# STM32G484 register map
File version: 2.8
CPU: CM4 r0p1, little endian, MPU, FPU, 4 interrupt priority bits
Registers are 32-bit, read-write, reset 0x0 unless marked. A register's access mark holds for its fields unless they carry their own. Offsets are from the block's base; [hi:lo] are bit positions; {n}, {i} and the like mark numbered series; 'fields as' and 'values as' point back to an identical list.

## HRTIM_Common — High Resolution Timer: Common functions
Base 0x40016B80
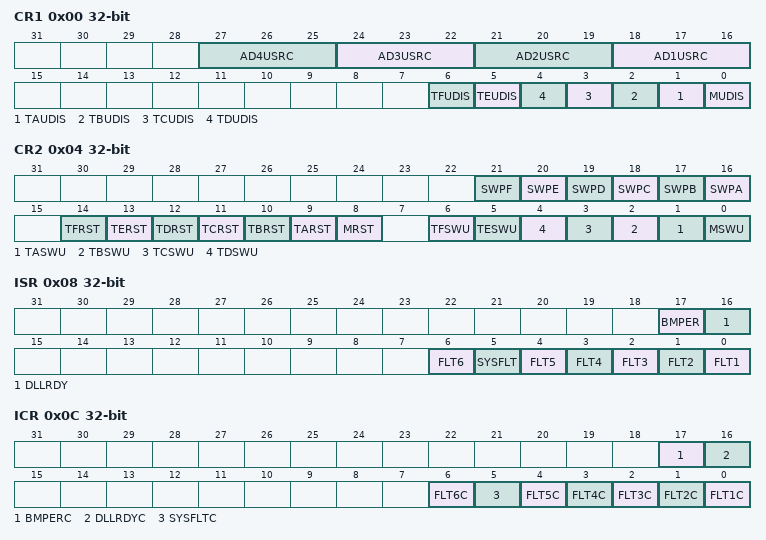
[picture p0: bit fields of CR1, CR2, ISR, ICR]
0x00 CR1 — Control Register 1
  [3n+15:3n+13] AD{n}USRC (n=1..4) — ADC Trigger {n} Update Source
    0=Master (ADC trigger update from master timer); 1=TimerA (ADC trigger update from timer A); 2=TimerB (ADC trigger update from timer B); 3=TimerC (ADC trigger update from timer C); 4=TimerD (ADC trigger update from timer D); 5=TimerE (ADC trigger update from timer E); 6=TimerF (ADC trigger update from timer F)
  [1] T{x}UDIS (x=A,B,C,D,E,F; step 1) — Timer {x} Update Disable
    0=Enabled (Timer update enabled); 1=Disabled (Timer update disabled)
  [0] MUDIS — Master Update Disable
    values as T{x}UDIS
0x04 CR2 — Control Register 2
  [16] SWP{x} (x=A,B,C,D,E,F; step 1) — Swap Timer {x} outputs
  [9] T{x}RST (x=A,B,C,D,E,F; step 1) — Timer {x} counter software reset
    1=Reset timer
  [8] MRST — Master Counter software reset
    1=Reset timer
  [1] T{x}SWU (x=A,B,C,D,E,F; step 1) — Timer {x} Software Update
    1=Update (Force immediate update)
  [0] MSWU — Master Timer Software update
    1=Update (Force immediate update)
0x08 ISR ro — Interrupt Status Register
  [17] BMPER — Burst mode Period Interrupt Flag
    0=NoEvent (No burst mode period interrupt occurred); 1=Event (Burst mode period interrupt occured)
  [16] DLLRDY — DLL Ready Interrupt Flag
    0=NoEvent (No DLL calibration ready interrupt occurred); 1=Event (DLL calibration ready interrupt occurred)
  [6] FLT6 — Fault 6 Interrupt Flag
    0=NoEvent (No fault interrupt occurred); 1=Event (Fault interrupt occurred)
  [5] SYSFLT — System Fault Interrupt Flag
    values as FLT6
  [n-1] FLT{n} (n=1..5) — Fault {n} Interrupt Flag
    values as FLT6
0x0C ICR wo — Interrupt Clear Register
  [all] fields
    1=Clears associated flag in ISR register
  [17] BMPERC write-1-clears — Burst mode period flag Clear
  [16] DLLRDYC write-1-clears — DLL Ready Interrupt flag Clear
  [6] FLT6C write-1-clears — Fault 6 Interrupt Flag Clear
  [5] SYSFLTC write-1-clears — System Fault Interrupt Flag Clear
  [n-1] FLT{n}C write-1-clears (n=1..5) — Fault {n} Interrupt Flag Clear
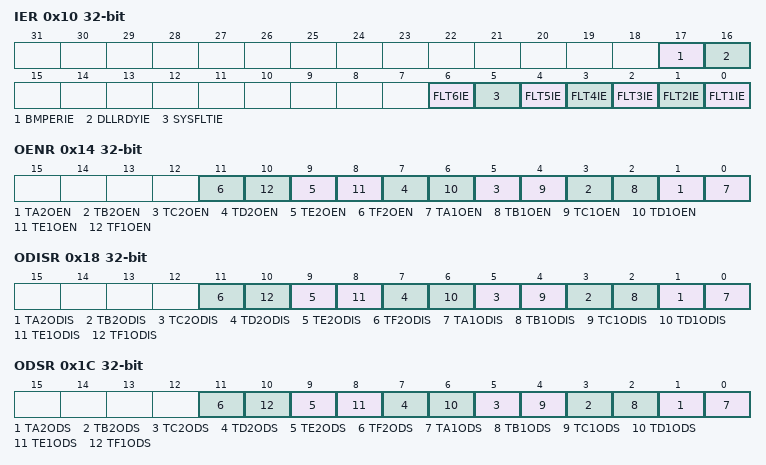
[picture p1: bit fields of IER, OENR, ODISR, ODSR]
0x10 IER — Interrupt Enable Register
  [17] BMPERIE — Burst mode period Interrupt Enable
    0=Disabled (Burst mode period interrupt disabled); 1=Enabled (Burst mode period interrupt enabled)
  [16] DLLRDYIE — DLL Ready Interrupt Enable
    0=Disabled (DLL ready interrupt disabled); 1=Enabled (DLL Ready interrupt enabled)
  [6] FLT6IE — Fault 6 Interrupt Enable
    0=Disabled (Fault interrupt disabled); 1=Enabled (Fault interrupt enabled)
  [5] SYSFLTIE — System Fault Interrupt Enable
    values as FLT6IE
  [n-1] FLT{n}IE (n=1..5) — Fault {n} Interrupt Enable
    values as FLT6IE
0x14 OENR — Output Enable Register
  [1] T{x}2OEN (x=A,B,C,D,E,F; step 2) write-1-sets — Timer {x} Output 2 Enable
    on read: 0=Disabled (Output disabled); 1=Enabled (Output enabled) | on write: 1=Enable output
  [0] T{x}1OEN (x=A,B,C,D,E,F; step 2) write-1-sets — Timer {x} Output 1 Enable
    values as T{x}2OEN
0x18 ODISR wo
  [1] T{x}2ODIS (x=A,B,C,D,E,F; step 2) write-1-sets — T{x}2ODIS
    1=Disable output
  [0] T{x}1ODIS (x=A,B,C,D,E,F; step 2) write-1-sets — T{x}1ODIS
    1=Disable output
0x1C ODSR ro — Output Disable Status Register
  [1] T{x}2ODS (x=A,B,C,D,E,F; step 2) — Timer {x} Output 2 disable status
    0=Idle (Output disabled in idle state); 1=Fault (Output disabled in fault state)
  [0] T{x}1ODS (x=A,B,C,D,E,F; step 2) — Timer {x} Output 1 disable status
    values as T{x}2ODS
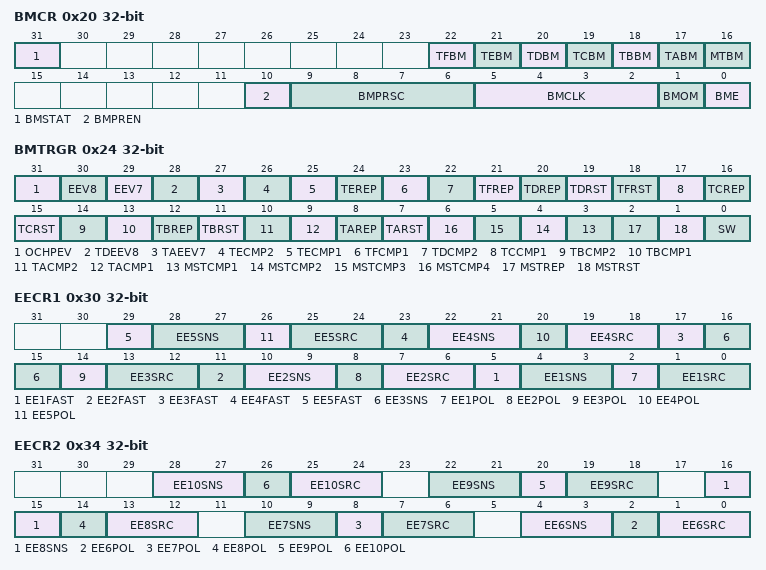
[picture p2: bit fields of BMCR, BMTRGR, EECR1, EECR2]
0x20 BMCR — Burst Mode Control Register
  [31] BMSTAT write-0-clears — Burst Mode Status
    on read: 0=Normal operation; 1=Burst operation ongoing | on write: 0=Cancel (Terminate burst mode)
  [17] T{x}BM (x=A,B,C,D,E,F; step 1) — Timer {x} Burst Mode
    0=Normal (Counter clock is maintained and timer operates normally); 1=Stopped (Counter clock is stopped and counter is reset)
  [16] MTBM — Master Timer Burst Mode
    values as T{x}BM
  [10] BMPREN — Burst Mode Preload Enable
    0=Disabled (Preload disabled: the write access is directly done into active registers); 1=Enabled (Preload enabled: the write access is done into preload registers)
  [9:6] BMPRSC — Burst Mode Prescaler
    0=Div1 (Clock not divided); 1=Div2 (Division by 2); 2=Div4 (Division by 4); 3=Div8 (Division by 8); 4=Div16 (Division by 16); 5=Div32 (Division by 32); 6=Div64 (Division by 64); 7=Div128 (Division by 128); 8=Div256 (Division by 256); 9=Div512 (Division by 512); 10=Div1024 (Division by 1024); 11=Div2048 (Division by 2048); 12=Div4096 (Division by 4096); 13=Div8192 (Division by 8192); 14=Div16384 (Division by 16384); 15=Div32768 (Division by 32768)
  [5:2] BMCLK — Burst Mode Clock source
    0=Master timer reset/roll-over; 1=Timer A counter reset/roll-over; 2=Timer B counter reset/roll-over; 3=Timer C counter reset/roll-over; 4=Timer D counter reset/roll-over; 5=Timer E counter reset/roll-over; {v}=Event{v-5} (On-chip Event {v-5} (BMClk[{v-5}]), acting as a burst mode counter clock) (v=6..9); 10=Clock (Prescaled f_HRTIM clock (as per BMPRSC[3:0] setting)
  [1] BMOM — Burst Mode operating mode
    0=Single-shot mode; 1=Continuous operation
  [0] BME — Burst Mode enable
    0=Disabled (Burst mode disabled); 1=Enabled (Burst mode enabled)
0x24 BMTRGR — BMTRG
  [31] OCHPEV
    0=NoEffect (Rising edge on an on-chip event has no effect); 1=Trigger (Rising edge on an on-chip event triggers a burst mode entry)
  [30] EEV8
    0=NoEffect (External event X has no effect); 1=Trigger (External event X triggers a burst mode entry)
  [29] EEV7
    values as EEV8
  [28] TDEEV8
    0=NoEffect (Timer X period following external event Y has no effect); 1=Trigger (Timer X period following external event Y triggers a burst mode entry)
  [27] TAEEV7 — Timer A period following external event 7
    values as TDEEV8
  [26] TECMP2
    0=NoEffect (Timer X compare Y event has no effect); 1=Trigger (Timer X compare Y event triggers a burst mode entry)
  [25] TECMP1
    values as TECMP2
  [24] TEREP
    0=NoEffect (Timer X repetition event has no effect); 1=Trigger (Timer X repetition event triggers a burst mode entry)
  [23] TFCMP1 — Timer F compare 1 event
    values as TECMP2
  [22] TDCMP2
    values as TECMP2
  [21] TFREP — Timer F repetition
    values as TEREP
  [20] TDREP
    values as TEREP
  [19] TDRST
    0=NoEffect (Timer X reset/roll-over event has no effect); 1=Trigger (Timer X reset/roll-over event triggers a burst mode entry)
  [18] TFRST — Timer F reset
    values as TDRST
  [17] TCCMP1
    values as TECMP2
  [16] TCREP
    values as TEREP
  [15] TCRST
    values as TDRST
  [14] TBCMP2
    values as TECMP2
  [13] TBCMP1
    values as TECMP2
  [12] TBREP
    values as TEREP
  [11] TBRST
    values as TDRST
  [10] TACMP2
    values as TECMP2
  [9] TACMP1
    values as TECMP2
  [8] TAREP
    values as TEREP
  [7] TARST
    values as TDRST
  [n+2] MSTCMP{n} (n=1..4)
    0=NoEffect (Master timer compare X event has no effect); 1=Trigger (Master timer compare X event triggers a burst mode entry)
  [2] MSTREP
    0=NoEffect (Master timer repetition event has no effect); 1=Trigger (Master timer repetition event triggers a burst mode entry)
  [1] MSTRST
    0=NoEffect (Master timer reset/roll-over event has no effect); 1=Trigger (Master timer reset/roll-over event triggers a burst mode entry)
  [0] SW
    0=NoEffect; 1=Trigger immediate burst mode operation
0x28 BMCMPR
  [15:0] BMCMP
0x2C BMPER — Burst Mode Period Register
  [15:0] BMPER — Burst mode Period
0x30 EECR1 — Timer External Event Control Register 1
  [6n-1] EE{n}FAST (n=1..5) — External Event {n} Fast mode
    0=Resynchronized (External event is re-synchronised by the HRTIM logic before acting on outputs); 1=Asynchronous (External event is acting asynchronously on outputs (low-latency mode))
  [6n-2:6n-3] EE{n}SNS (n=1..5) — External Event {n} Sensitivity
    0=Active (On active level defined by EExPOL bit); 1=Rising edge; 2=Falling edge; 3=Both edges
  [6n-4] EE{n}POL (n=1..5) — External Event {n} Polarity
    0=ActiveHigh (External event is active high); 1=ActiveLow (External event is active low)
  [6n-5:6n-6] EE{n}SRC (n=1..5) — External Event {n} Source
    {v}=Src{v+1} (Source {v+1}) (v=0..3)
0x34 EECR2 — Timer External Event Control Register 2
  [6n-32:6n-33] EE{n}SNS (n=6..10) — EE{n}SNS
    values as EECR1.EE1SNS
  [6n-34] EE{n}POL (n=6..10) — EE{n}POL
    values as EECR1.EE1POL
  [6n-35:6n-36] EE{n}SRC (n=6..10) — EE{n}SRC
    {v}=Src{v+1} (Source {v+1}) (v=0..3)
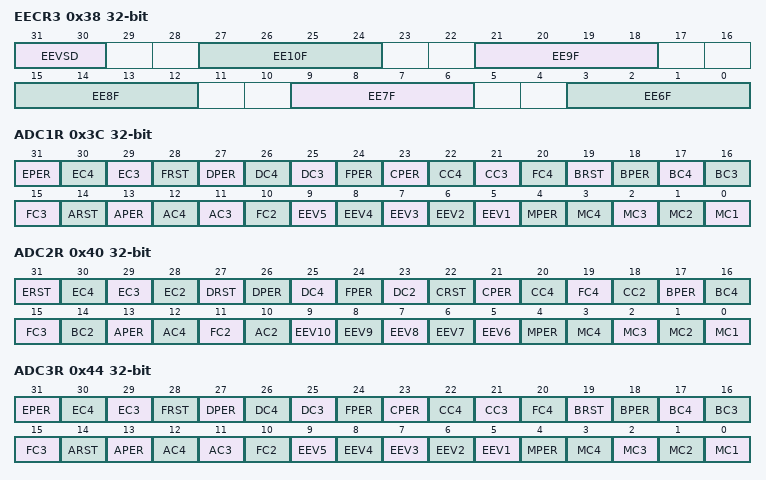
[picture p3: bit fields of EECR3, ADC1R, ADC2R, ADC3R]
0x38 EECR3 — Timer External Event Control Register 3
  [31:30] EEVSD
    0=Div1 (f_EEVS=f_HRTIM); 1=Div2 (f_EEVS=f_HRTIM/2); 2=Div4 (f_EEVS=f_HRTIM/4); 3=Div8 (f_EEVS=f_HRTIM/8)
  [6n-33:6n-36] EE{n}F (n=6..10) — EE{n}F
    0=Disabled (Filter disabled); 1=Div1_N2 (f_SAMPLING=f_HRTIM, N=2); 2=Div1_N4 (f_SAMPLING=f_HRTIM, N=4); 3=Div1_N8 (f_SAMPLING=f_HRTIM, N=8); 4=Div2_N6 (f_SAMPLING=f_EEVS/2, N=6); 5=Div2_N8 (f_SAMPLING=f_EEVS/2, N=8); 6=Div4_N6 (f_SAMPLING=f_EEVS/4, N=6); 7=Div4_N8 (f_SAMPLING=f_EEVS/4, N=8); 8=Div8_N6 (f_SAMPLING=f_EEVS/8, N=6); 9=Div8_N8 (f_SAMPLING=f_EEVS/8, N=8); 10=Div16_N5 (f_SAMPLING=f_EEVS/16, N=5); 11=Div16_N6 (f_SAMPLING=f_EEVS/16, N=6); 12=Div16_N8 (f_SAMPLING=f_EEVS/16, N=8); 13=Div32_N5 (f_SAMPLING=f_EEVS/32, N=5); 14=Div32_N6 (f_SAMPLING=f_EEVS/32, N=6); 15=Div32_N8 (f_SAMPLING=f_EEVS/32, N=8)
0x3C ADC1R — ADC Trigger 1 Register
  [31] EPER — ADC trigger 1 on Timer E Period
    0=Disabled (No generation of ADC trigger on timer period event); 1=Enabled (Generation of ADC trigger on timer period event)
  [30] EC4 — ADC trigger 1 on Timer E compare 4
    0=Disabled (No generation of ADC trigger on timer compare event); 1=Enabled (Generation of ADC trigger on timer compare event)
  [29] EC3 — ADC trigger 1 on Timer E compare 3
    values as EC4
  [28] FRST — Bit 28 - ADC trigger 1 on timer F reset and counter roll-over
    0=Disabled (No generation of ADC trigger on timer reset and roll-over); 1=Enabled (Generation of ADC trigger on timer reset and roll-over)
  [27] DPER — ADC trigger 1 on Timer D Period
    values as EPER
  [26] DC4 — ADC trigger 1 on Timer D compare 4
    values as EC4
  [25] DC3 — ADC trigger 1 on Timer D compare 3
    values as EC4
  [24] FPER — Bit 24 - ADC trigger 1 on timer F period
    values as EPER
  [23] CPER — ADC trigger 1 on Timer C Period
    values as EPER
  [22] CC4 — ADC trigger 1 on Timer C compare 4
    values as EC4
  [21] CC3 — ADC trigger 1 on Timer C compare 3
    values as EC4
  [20] FC4 — Bit 20 - ADC trigger 1 on timer F compare 4
    values as EC4
  [19] BRST — ADC trigger 1 on Timer B Reset
    values as FRST
  [18] BPER — ADC trigger 1 on Timer B Period
    values as EPER
  [17] BC4 — ADC trigger 1 on Timer B compare 4
    values as EC4
  [16] BC3 — ADC trigger 1 on Timer B compare 3
    values as EC4
  [15] FC3 — Bit 15 - ADC trigger 1 on timer F compare 3
    values as EC4
  [14] ARST — ADC trigger 1 on Timer A Reset
    values as FRST
  [13] APER — ADC trigger 1 on Timer A Period
    values as EPER
  [12] AC4 — ADC trigger 1 on Timer A compare 4
    values as EC4
  [11] AC3 — ADC trigger 1 on Timer A compare 3
    values as EC4
  [10] FC2 — Bit 10 - ADC trigger 1 on timer F compare 2
    values as EC4
  [n+4] EEV{n} (n=1..5) — ADC trigger 1 on External Event {n}
    0=Disabled (No generation of ADC trigger on external event); 1=Enabled (Generation of ADC trigger on external event)
  [4] MPER — ADC trigger 1 on Master Period
    values as EPER
  [n-1] MC{n} (n=1..4) — ADC trigger 1 on Master Compare {n}
    0=Disabled (No generation of ADC trigger on master compare event); 1=Enabled (Generation of ADC trigger on master compare event)
0x40 ADC2R — ADC Trigger 2 Register
  [31] ERST — ADC trigger 2 on Timer E Reset
    values as ADC1R.FRST
  [30] EC4 — ADC trigger 2 on Timer E compare 4
    values as ADC1R.EC4
  [29] EC3 — ADC trigger 2 on Timer E compare 3
    values as ADC1R.EC4
  [28] EC2 — ADC trigger 2 on Timer E compare 2
    values as ADC1R.EC4
  [27] DRST — ADC trigger 2 on Timer D Reset
    values as ADC1R.FRST
  [26] DPER — ADC trigger 2 on Timer D Period
    values as ADC1R.EPER
  [25] DC4 — ADC trigger 2 on Timer D compare 4
    values as ADC1R.EC4
  [24] FPER — Bit 24 - ADC trigger 2 on timer F period
    values as ADC1R.EPER
  [23] DC2 — ADC trigger 2 on Timer D compare 2
    values as ADC1R.EC4
  [22] CRST — ADC trigger 2 on Timer C Reset
    values as ADC1R.FRST
  [21] CPER — ADC trigger 2 on Timer C Period
    values as ADC1R.EPER
  [20] CC4 — ADC trigger 2 on Timer C compare 4
    values as ADC1R.EC4
  [19] FC4 — Bit 19 - ADC trigger 2 on timer F compare 4
    values as ADC1R.EC4
  [18] CC2 — ADC trigger 2 on Timer C compare 2
    values as ADC1R.EC4
  [17] BPER — ADC trigger 2 on Timer B Period
    values as ADC1R.EPER
  [16] BC4 — ADC trigger 2 on Timer B compare 4
    values as ADC1R.EC4
  [15] FC3 — Bit 15 - ADC trigger 2 on timer F compare 3
    values as ADC1R.EC4
  [14] BC2 — ADC trigger 2 on Timer B compare 2
    values as ADC1R.EC4
  [13] APER — ADC trigger 2 on Timer A Period
    values as ADC1R.EPER
  [12] AC4 — ADC trigger 2 on Timer A compare 4
    values as ADC1R.EC4
  [11] FC2 — Bit 11 - ADC trigger 3 on timer F compare 2
    values as ADC1R.EC4
  [10] AC2 — ADC trigger 2 on Timer A compare 2
    values as ADC1R.EC4
  [n-1] EEV{n} (n=6..10) — ADC trigger 2 on External Event {n}
    values as ADC1R.EEV1
  [4] MPER — ADC trigger 2 on Master Period
    values as ADC1R.EPER
  [n-1] MC{n} (n=1..4) — ADC trigger 2 on Master Compare {n}
    values as ADC1R.MC1
0x44 ADC3R — ADC Trigger 3 Register
  fields as ADC1R
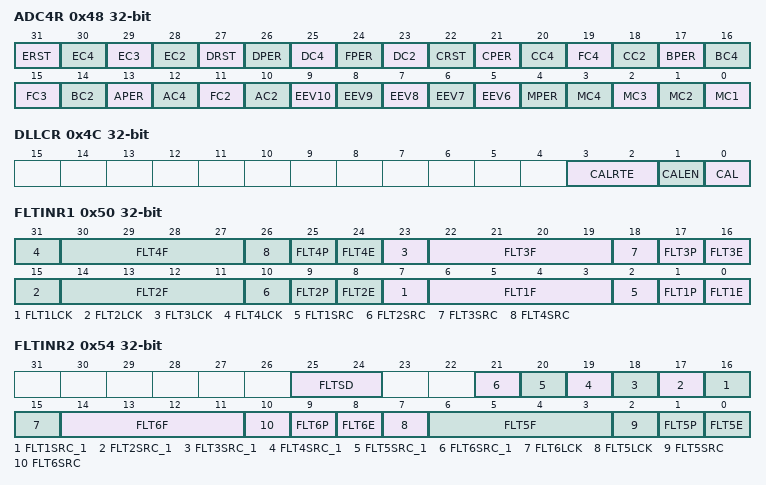
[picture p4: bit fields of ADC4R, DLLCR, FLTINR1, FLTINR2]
0x48 ADC4R — ADC Trigger 4 Register
  fields as ADC2R
0x4C DLLCR — DLL Control Register
  [3:2] CALRTE — DLL Calibration rate
    0=Clk1048576 (1048576*t_HRTIM (6.168 ms for fHRTIM = 170 MHz)); 1=Clk131072 (131072*t_HRTIM (771 µs for f_HRTIM = 170 MHz)); 2=Clk16384 (16384*t_HRTIM (96 µs for f_HRTIM = 170 MHz)); 3=Clk2048 (2048*t_HRTIM (12 µs for f_HRTIM = 170 MHz))
  [1] CALEN — DLL Calibration Enable
    0=Disabled (Periodic calibration disabled); 1=Enabled (Calibration is performed periodically, as per CALRTE setting)
  [0] CAL — DLL Calibration Start
    1=Start (Calibration start)
0x50 FLTINR1 — HRTIM Fault Input Register 1
  [8n-1] FLT{n}LCK (n=1..4)
    on read: 0=Unlocked (Fault bits are read/write); 1=Locked (Fault bits are read-only) | on write: 1=Lock corresponding fault bits
  [8n-2:8n-5] FLT{n}F (n=1..4) — FLT{n}F
    0=Disabled (No filter, FLTx acts asynchronously); 1=Div1_N2 (f_SAMPLING=f_HRTIM, N=2); 2=Div1_N4 (f_SAMPLING=f_HRTIM, N=4); 3=Div1_N8 (f_SAMPLING=f_HRTIM, N=8); 4=Div2_N6 (f_SAMPLING=f_HRTIM/2, N=6); 5=Div2_N8 (f_SAMPLING=f_HRTIM/2, N=8); 6=Div4_N6 (f_SAMPLING=f_HRTIM/4, N=6); 7=Div4_N8 (f_SAMPLING=f_HRTIM/4, N=8); 8=Div8_N6 (f_SAMPLING=f_HRTIM/8, N=6); 9=Div8_N8 (f_SAMPLING=f_HRTIM/8, N=8); 10=Div16_N5 (f_SAMPLING=f_HRTIM/16, N=5); 11=Div16_N6 (f_SAMPLING=f_HRTIM/16, N=6); 12=Div16_N8 (f_SAMPLING=f_HRTIM/16, N=8); 13=Div32_N5 (f_SAMPLING=f_HRTIM/32, N=5); 14=Div32_N6 (f_SAMPLING=f_HRTIM/32, N=6); 15=Div32_N8 (f_SAMPLING=f_HRTIM/32, N=8)
  [8n-6] FLT{n}SRC (n=1..4) — Fault {n} source
    0=Input (Fault input is FLTx input pin); 1=CompOutput (Fault input is connected to a COMPx output)
  [8n-7] FLT{n}P (n=1..4) — FLT{n}P
    0=ActiveLow (Fault input is active low); 1=ActiveHigh (Fault input is active high)
  [8n-8] FLT{n}E (n=1..4) — FLT{n}E
    0=Disabled (Fault input disabled); 1=Enabled (Fault input enabled)
0x54 FLTINR2 — HRTIM Fault Input Register 2
  [25:24] FLTSD
    0=Div1 (f_FLTS=f_HRTIM); 1=Div2 (f_FLTS=f_HRTIM/2); 2=Div4 (f_FLTS=f_HRTIM/4); 3=Div8 (f_FLTS=f_HRTIM/8)
  [n+15] FLT{n}SRC_1 (n=1..6) — Fault {n} source bit 1
    0=Default (As described in FLTxSRC); 1=Eev (Fault input is EEV5_muxout input pin (when FLTxSRC == 0) / reserved)
  [15] FLT6LCK
    values as FLTINR1.FLT1LCK
  [7] FLT5LCK
    values as FLTINR1.FLT1LCK
  [8n-34:8n-37] FLT{n}F (n=5..6) — FLT{n}F
    values as FLTINR1.FLT1F
  [8n-38] FLT{n}SRC (n=5..6) — Fault {n} source
    values as FLTINR1.FLT1SRC
  [8n-39] FLT{n}P (n=5..6) — FLT{n}P
    values as FLTINR1.FLT1P
  [8n-40] FLT{n}E (n=5..6) — FLT{n}E
    values as FLTINR1.FLT1E
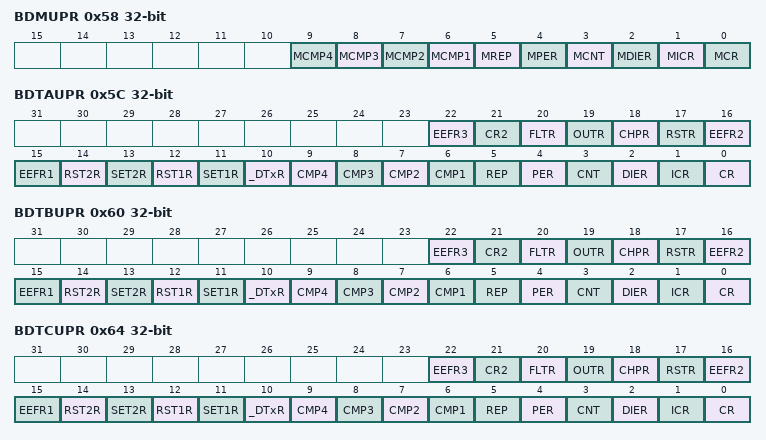
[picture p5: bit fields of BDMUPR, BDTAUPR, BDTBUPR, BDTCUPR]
0x58 BDMUPR — BDMUPDR
  [all] fields
    0=NotUpdated (Register not updated by burst DMA access); 1=Updated (Register updated by burst DMA access)
  [n+5] MCMP{n} (n=1..4)
  [5] MREP
  [4] MPER
  [3] MCNT
  [2] MDIER
  [1] MICR
  [0] MCR
0x5C BDTAUPR — Burst DMA Timerx update Register
  [all] fields
    values as the fields of BDMUPR
  [22] EEFR3 — TIMxEEFR3
  [21] CR2 — TIMxCR2
  [20] FLTR — HRTIM_FLTxR register update enable
  [19] OUTR — HRTIM_OUTxR register update enable
  [18] CHPR — HRTIM_CHPxR register update enable
  [17] RSTR — HRTIM_RSTxR register update enable
  [16] EEFR2 — HRTIM_EEFxR2 register update enable
  [15] EEFR1 — HRTIM_EEFxR1 register update enable
  [14] RST2R — HRTIM_RST2xR register update enable
  [13] SET2R — HRTIM_SET2xR register update enable
  [12] RST1R — HRTIM_RST1xR register update enable
  [11] SET1R — HRTIM_SET1xR register update enable
  [10] _DTxR — HRTIM_DTxR register update enable
  [n+5] CMP{n} (n=1..4) — HRTIM_CMP{n}xR register update enable
  [5] REP — HRTIM_REPxR register update enable
  [4] PER — HRTIM_PERxR register update enable
  [3] CNT — HRTIM_CNTxR register update enable
  [2] DIER — HRTIM_TIMxDIER register update enable
  [1] ICR — HRTIM_TIMxICR register update enable
  [0] CR — HRTIM_TIMxCR register update enable
0x60 BDTBUPR — Burst DMA Timerx update Register
  fields as BDTAUPR
0x64 BDTCUPR — Burst DMA Timerx update Register
  fields as BDTAUPR
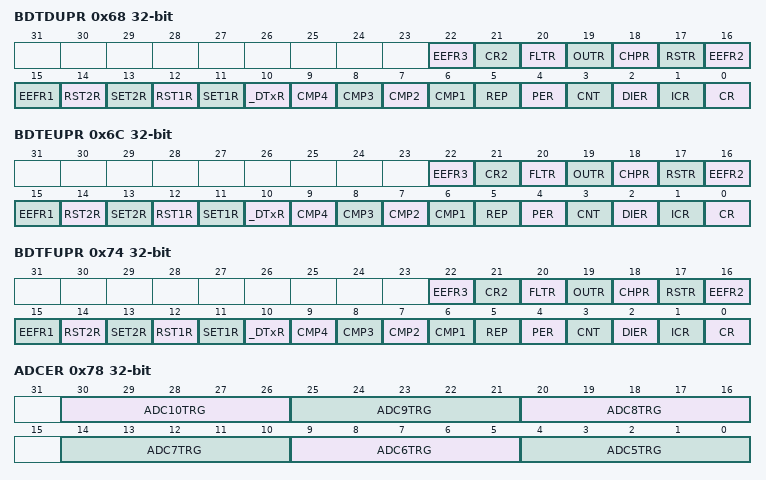
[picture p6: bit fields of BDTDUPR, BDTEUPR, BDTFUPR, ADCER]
0x68 BDTDUPR — Burst DMA Timerx update Register
  fields as BDTAUPR
0x6C BDTEUPR — Burst DMA Timerx update Register
  fields as BDTAUPR
0x70 BDMADR wo — Burst DMA Data Register
  [31:0] BDMADR — Burst DMA Data register
0x74 BDTFUPR — Burst DMA Timerx update Register
  fields as BDTAUPR
0x78 ADCER — HRTIM ADC Extended Trigger Register
  [30:26] ADC10TRG, [25:21] ADC9TRG, [20:16] ADC8TRG, [14:10] ADC7TRG, [9:5] ADC6TRG, [4:0] ADC5TRG
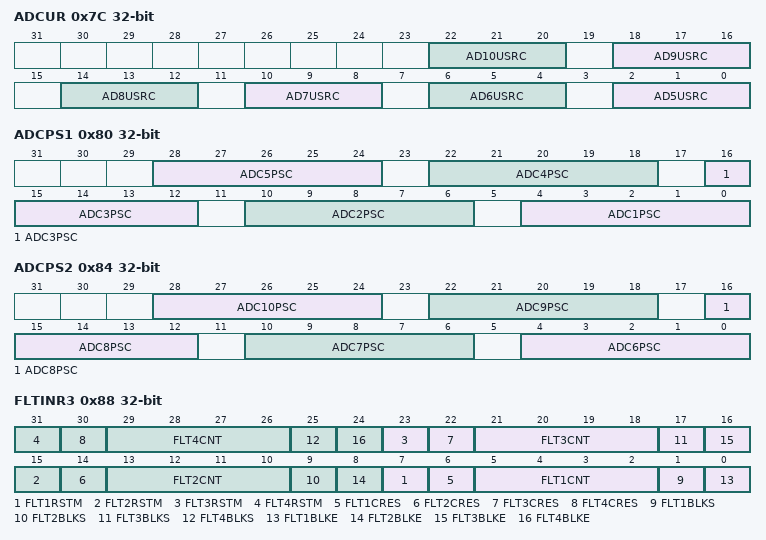
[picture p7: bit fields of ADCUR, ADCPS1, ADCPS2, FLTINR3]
0x7C ADCUR — HRTIM ADC Trigger Update Register
  [4n-18:4n-20] AD{n}USRC (n=5..10)
0x80 ADCPS1 — HRTIM ADC Post Scaler Register 1
  [6n-2:6n-6] ADC{n}PSC (n=1..5)
0x84 ADCPS2 — HRTIM ADC Post Scaler Register 2
  [6n-32:6n-36] ADC{n}PSC (n=6..10)
0x88 FLTINR3 — HRTIM Fault Input Register 3
  [8n-1] FLT{n}RSTM (n=1..4)
  [8n-2] FLT{n}CRES (n=1..4) — FLT{n}CRES
  [8n-3:8n-6] FLT{n}CNT (n=1..4) — FLT{n}CNT
  [8n-7] FLT{n}BLKS (n=1..4) — FLT{n}BLKS
  [8n-8] FLT{n}BLKE (n=1..4) — FLT{n}BLKE
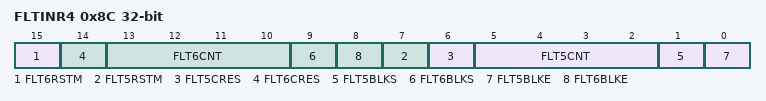
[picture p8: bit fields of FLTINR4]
0x8C FLTINR4 — HRTIM Fault Input Register 4
  [15] FLT6RSTM
  [7] FLT5RSTM
  [8n-34] FLT{n}CRES (n=5..6) — FLT{n}CRES
  [8n-35:8n-38] FLT{n}CNT (n=5..6) — FLT{n}CNT
  [8n-39] FLT{n}BLKS (n=5..6) — FLT{n}BLKS
  [8n-40] FLT{n}BLKE (n=5..6) — FLT{n}BLKE
